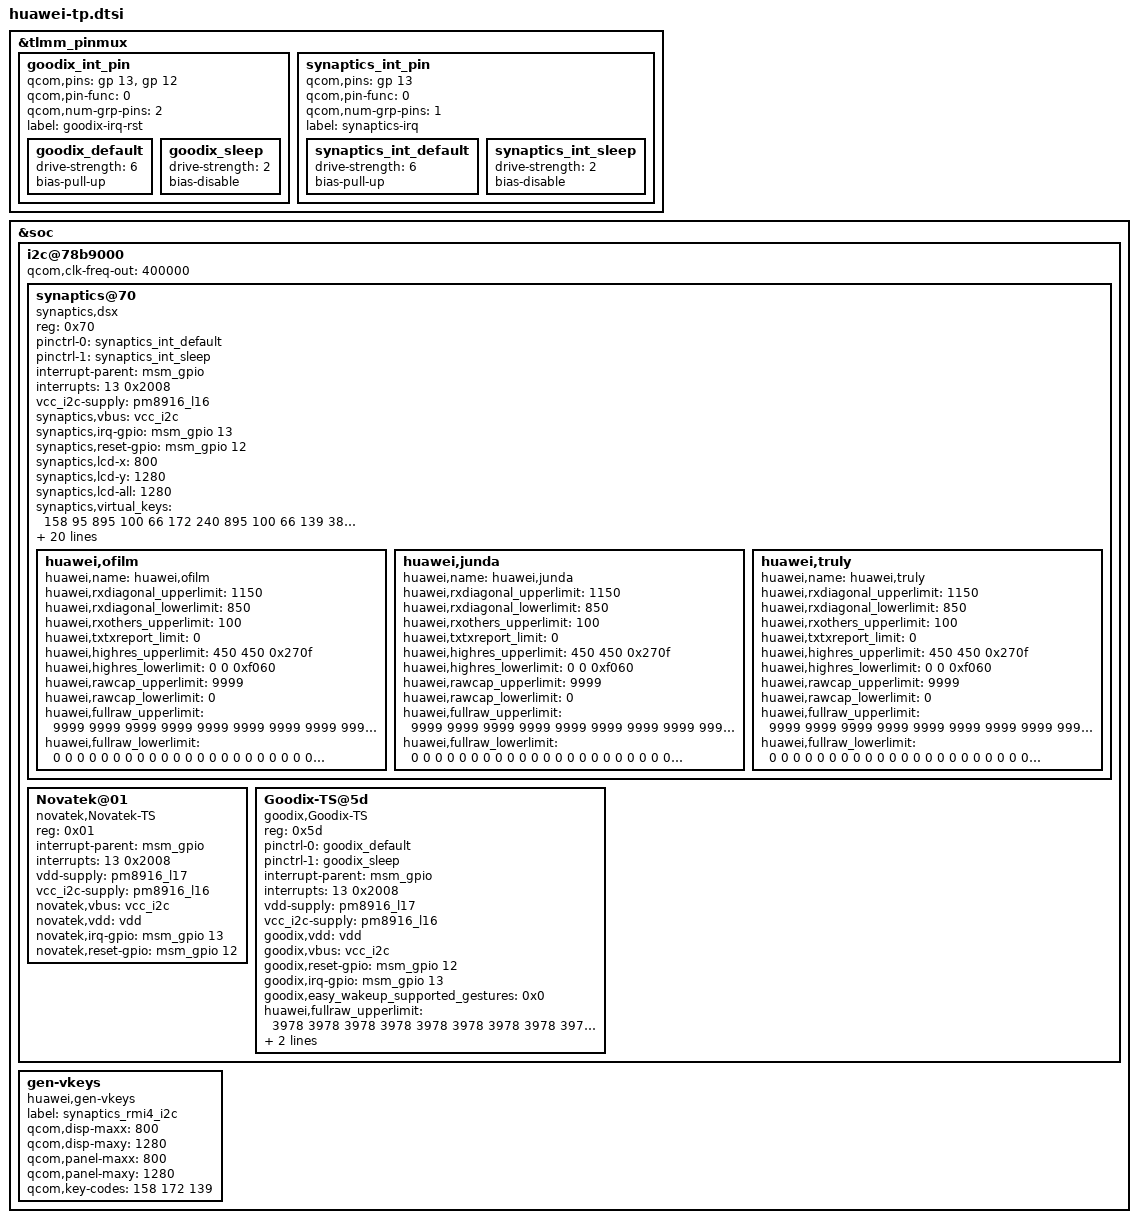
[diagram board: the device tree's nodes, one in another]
/*Add synaptics new driver "Synaptics DSX I2C V2.0"*/
/*Change i2c frepuence from 100kHZ to 400kHZ*/
/*Open fast-relax config for better gesture performance*/
&tlmm_pinmux {

	goodix_int_pin {
		qcom,pins = <&gp 13>,<&gp 12>;
		qcom,pin-func = <0>;
		qcom,num-grp-pins = <2>;
		label = "goodix-irq-rst";
		goodix_default: goodix_default {
			drive-strength = <6>;
			bias-pull-up;
		};
		goodix_sleep: goodix_sleep {
			drive-strength = <2>;
			bias-disable;
		};
	};
	synaptics_int_pin {
		qcom,pins = <&gp 13>;
		qcom,pin-func = <0>;
		qcom,num-grp-pins = <1>;
		label = "synaptics-irq";
		synaptics_int_default: synaptics_int_default {
			drive-strength = <6>;
			bias-pull-up;
		};
		synaptics_int_sleep: synaptics_int_sleep {
			drive-strength = <2>;
			bias-disable;
		};
	};
};
&soc {
	i2c@78b9000 { /* BLSP1 QUP5 */
		status = "ok";
		#address-cells = <1>;
		#size-cells = <0>;
		qcom,clk-freq-out = <400000>;
		synaptics@70 {
			compatible = "synaptics,dsx";
			reg = <0x70>;
			pinctrl-names = "active","sleep";
			pinctrl-0 = <&synaptics_int_default>;
			pinctrl-1 = <&synaptics_int_sleep>;
			interrupt-parent = <&msm_gpio>;
			interrupts = <13 0x2008>;
			/*vdd-supply = <&pm8916_l17>;*/
			vcc_i2c-supply = <&pm8916_l16>;
			/* Some of qcom's param will not be replaced by huawei in dtb, */
			/* just ignore them:such as "pinctrl-names","pinctrl-0","pinctrl-1", */
			/* "synaptics,display-coords","synaptics,panel-coords","synaptics,i2c-pull-up", */
			/* "synaptics,power-down","synaptics,disable-gpios"*/
			/*synaptics,vdd = "vdd";*/
			synaptics,vbus = "vcc_i2c";
			synaptics,irq-gpio = <&msm_gpio 13 0x2008>;
			synaptics,reset-gpio = <&msm_gpio 12 0x0>;
			synaptics,lcd-x = <800>;
			synaptics,lcd-y = <1280>;
			synaptics,lcd-all = <1280>;
			synaptics,virtual_keys = /* KeyCode CenterX CenterY Width Height */
				/* KEY_BACK */
				<158 95 895 100 66
				/* KEY_HOME(172) */
				172 240 895 100 66
				/* KEY_MENU */
				139 385 895 100 66>;

			/* SYNAPTICS_WAKE_UP_GESTURE_FLAG:'1'->enabled,'0'->disabled */
			/*IC flash is not enough for holster,so fw del one gesture*/
			synaptics,gesture_enabled = <0>;
			/* Gestures that supported:                           */
			/* bit0  Double tap                                        */
			/* bit1  Single finger slide from left to right     */
			/* bit2  Single finger slide from right to left     */
			/* bit3  Single finger slide from top to bottom  */
			/* bit4  Single finger slide from bottom to top  */
			/* bit5  Double finger slide from top to bottom--disable for holster*/
			/* bit6  Single finger slide circle                     */
			/* bit7  Single finger write letter c                  */
			/* bit8  Single finger write letter e                  */
			/* bit9  Single finger write letter m                 */
			/* bit10 Single finger write letter w                 */
			/* bit11 Palm off screen                                */
			synaptics,easy_wakeup_supported_gestures = <0xFDF>;

			/*Defination of report key value  for different gestures*/
			synaptics,easy_wakeup_gesture_keys = 
			<	59 /*0.Double tap:KEY_F1*/
				60 /*1.Single finger slide from left to right*/
				61 /*2.Single finger slide from right to left:KEY_F3*/
				62 /*3.Single finger slide from top to bottom*/
				63 /*4.Single finger slide from bottom to top:KEY_F5*/
				64 /*5.Single finger slide circle clockwise*/
				65 /*6.Single finger slide circle counter-clockwise*/
				66 /*7.Single finger write letter c*/
				67 /*8.Single finger write letter e:KEY_F9*/
				68 /*9.Single finger write letter m*/
				87 /*10.Single finger write letter w:KEY_F11*/
				88 /*11.Palm off screen*/
			>;

			/* Double-tap-zone defined by huawei */
			/* Shielded area is:1cm left,1cm right,3cm up,2cm down */
			huawei,dtz_x0 = <77>;
			huawei,dtz_y0 = <233>;
			huawei,dtz_x1 = <403>;
			huawei,dtz_y1 = <699>;

			/* SYNAPTICS_GLOVE_FUNCTION_FLAG:'1'->enabled,'0'->disabled*/
			synaptics,glove_enabled = <0>;
			/*After reduce power-consumption by exit reduce mode,*/
			/*we have to reduce f-r rate to make sure gesture work fine*/
			synaptics,fast_relax_gesture = <30>;
			/*Holster support flag*/
			/*synaptics,holster_supported = <0>;*/
			/*dwt represent doze wakeup threshold in gesture mode*/
			synaptics,ofilm_dwt = <30>;
			synaptics,truly_dwt = <30>;
			synaptics,junda_dwt = <30>;
			synaptics,vdd_ctrl_by_lcd = <1>;

			synaptics,reset-on-status = <0>;
			synaptics,power-delay-ms = <160>;
			synaptics,reset-delay-ms = <100>;
			synaptics,reset-active-ms = <90>;
			synaptics,product_name = "t18p0";

			/*capacitance self-adapt*/
			/*To adjust the cutting angle threshold to the maximum range*/
			huawei,ofilm {
				huawei,name = "huawei,ofilm";
				huawei,rxdiagonal_upperlimit = <1150>;
				huawei,rxdiagonal_lowerlimit = <850>;
				huawei,rxothers_upperlimit = <100>;
				huawei,txtxreport_limit = <0>;
				huawei,highres_upperlimit = <450 450 0x270f>;/*0x270f==9999*/
				huawei,highres_lowerlimit = <0 0 0xf060>;/*0xf060==-4000*/
				huawei,rawcap_upperlimit = <9999>;
				huawei,rawcap_lowerlimit = <0>;

				huawei,fullraw_upperlimit =
					<9999 9999 9999 9999 9999 9999 9999 9999 9999 9999 9999 9999 9999 9999 9999 9999 9999 9999 9999 9999 9999 9999 9999 9999 
					9999 9999 9999 9999 9999 9999 9999 9999 9999 9999 9999 9999 9999 9999 9999 9999 9999 9999 9999 9999 9999 9999 9999 9999 
					9999 9999 9999 9999 9999 9999 9999 9999 9999 9999 9999 9999 9999 9999 9999 9999 9999 9999 9999 9999 9999 9999 9999 9999 
					9999 9999 9999 9999 9999 9999 9999 9999 9999 9999 9999 9999 9999 9999 9999 9999 9999 9999 9999 9999 9999 9999 9999 9999 
					9999 9999 9999 9999 9999 9999 9999 9999 9999 9999 9999 9999 9999 9999 9999 9999 9999 9999 9999 9999 9999 9999 9999 9999 
					9999 9999 9999 9999 9999 9999 9999 9999 9999 9999 9999 9999 9999 9999 9999 9999 9999 9999 9999 9999 9999 9999 9999 9999 
					9999 9999 9999 9999 9999 9999 9999 9999 9999 9999 9999 9999 9999 9999 9999 9999 9999 9999 9999 9999 9999 9999 9999 9999 
					9999 9999 9999 9999 9999 9999 9999 9999 9999 9999 9999 9999 9999 9999 9999 9999 9999 9999 9999 9999 9999 9999 9999 9999 
					9999 9999 9999 9999 9999 9999 9999 9999 9999 9999 9999 9999 9999 9999 9999 9999 9999 9999 9999 9999 9999 9999 9999 9999 
					9999 9999 9999 9999 9999 9999 9999 9999 9999 9999 9999 9999 9999 9999 9999 9999 9999 9999 9999 9999 9999 9999 9999 9999 
					9999 9999 9999 9999 9999 9999 9999 9999 9999 9999 9999 9999 9999 9999 9999 9999 9999 9999 9999 9999 9999 9999 9999 9999 
					9999 9999 9999 9999 9999 9999 9999 9999 9999 9999 9999 9999 9999 9999 9999 9999 9999 9999 9999 9999 9999 9999 9999 9999 
					9999 9999 9999 9999 9999 9999 9999 9999 9999 9999 9999 9999 9999 9999 9999 9999 9999 9999 9999 9999 9999 9999 9999 9999>;

				huawei,fullraw_lowerlimit =
					<0 0 0 0 0 0 0 0 0 0 0 0 0 0 0 0 0 0 0 0 0 0 0 0 
					0 0 0 0 0 0 0 0 0 0 0 0 0 0 0 0 0 0 0 0 0 0 0 0 
					0 0 0 0 0 0 0 0 0 0 0 0 0 0 0 0 0 0 0 0 0 0 0 0 
					0 0 0 0 0 0 0 0 0 0 0 0 0 0 0 0 0 0 0 0 0 0 0 0 
					0 0 0 0 0 0 0 0 0 0 0 0 0 0 0 0 0 0 0 0 0 0 0 0 
					0 0 0 0 0 0 0 0 0 0 0 0 0 0 0 0 0 0 0 0 0 0 0 0 
					0 0 0 0 0 0 0 0 0 0 0 0 0 0 0 0 0 0 0 0 0 0 0 0 
					0 0 0 0 0 0 0 0 0 0 0 0 0 0 0 0 0 0 0 0 0 0 0 0 
					0 0 0 0 0 0 0 0 0 0 0 0 0 0 0 0 0 0 0 0 0 0 0 0 
					0 0 0 0 0 0 0 0 0 0 0 0 0 0 0 0 0 0 0 0 0 0 0 0  
					0 0 0 0 0 0 0 0 0 0 0 0 0 0 0 0 0 0 0 0 0 0 0 0 
					0 0 0 0 0 0 0 0 0 0 0 0 0 0 0 0 0 0 0 0 0 0 0 0 
					0 0 0 0 0 0 0 0 0 0 0 0 0 0 0 0 0 0 0 0 0 0 0 0>;
			};
			huawei,junda {
				huawei,name = "huawei,junda";
				huawei,rxdiagonal_upperlimit = <1150>;
				huawei,rxdiagonal_lowerlimit = <850>;
				huawei,rxothers_upperlimit = <100>;
				huawei,txtxreport_limit = <0>;
				huawei,highres_upperlimit = <450 450 0x270f>;/*0x270f==9999*/
				huawei,highres_lowerlimit = <0 0 0xf060>;/*0xf060==-4000*/
				huawei,rawcap_upperlimit = <9999>;
				huawei,rawcap_lowerlimit = <0>;

				huawei,fullraw_upperlimit =
					<9999 9999 9999 9999 9999 9999 9999 9999 9999 9999 9999 9999 9999 9999 9999 9999 9999 9999 9999 9999 9999 9999 9999 9999 
					9999 9999 9999 9999 9999 9999 9999 9999 9999 9999 9999 9999 9999 9999 9999 9999 9999 9999 9999 9999 9999 9999 9999 9999 
					9999 9999 9999 9999 9999 9999 9999 9999 9999 9999 9999 9999 9999 9999 9999 9999 9999 9999 9999 9999 9999 9999 9999 9999 
					9999 9999 9999 9999 9999 9999 9999 9999 9999 9999 9999 9999 9999 9999 9999 9999 9999 9999 9999 9999 9999 9999 9999 9999 
					9999 9999 9999 9999 9999 9999 9999 9999 9999 9999 9999 9999 9999 9999 9999 9999 9999 9999 9999 9999 9999 9999 9999 9999 
					9999 9999 9999 9999 9999 9999 9999 9999 9999 9999 9999 9999 9999 9999 9999 9999 9999 9999 9999 9999 9999 9999 9999 9999 
					9999 9999 9999 9999 9999 9999 9999 9999 9999 9999 9999 9999 9999 9999 9999 9999 9999 9999 9999 9999 9999 9999 9999 9999 
					9999 9999 9999 9999 9999 9999 9999 9999 9999 9999 9999 9999 9999 9999 9999 9999 9999 9999 9999 9999 9999 9999 9999 9999 
					9999 9999 9999 9999 9999 9999 9999 9999 9999 9999 9999 9999 9999 9999 9999 9999 9999 9999 9999 9999 9999 9999 9999 9999 
					9999 9999 9999 9999 9999 9999 9999 9999 9999 9999 9999 9999 9999 9999 9999 9999 9999 9999 9999 9999 9999 9999 9999 9999 
					9999 9999 9999 9999 9999 9999 9999 9999 9999 9999 9999 9999 9999 9999 9999 9999 9999 9999 9999 9999 9999 9999 9999 9999 
					9999 9999 9999 9999 9999 9999 9999 9999 9999 9999 9999 9999 9999 9999 9999 9999 9999 9999 9999 9999 9999 9999 9999 9999 
					9999 9999 9999 9999 9999 9999 9999 9999 9999 9999 9999 9999 9999 9999 9999 9999 9999 9999 9999 9999 9999 9999 9999 9999>;

				huawei,fullraw_lowerlimit =
					<0 0 0 0 0 0 0 0 0 0 0 0 0 0 0 0 0 0 0 0 0 0 0 0 
					0 0 0 0 0 0 0 0 0 0 0 0 0 0 0 0 0 0 0 0 0 0 0 0 
					0 0 0 0 0 0 0 0 0 0 0 0 0 0 0 0 0 0 0 0 0 0 0 0 
					0 0 0 0 0 0 0 0 0 0 0 0 0 0 0 0 0 0 0 0 0 0 0 0 
					0 0 0 0 0 0 0 0 0 0 0 0 0 0 0 0 0 0 0 0 0 0 0 0 
					0 0 0 0 0 0 0 0 0 0 0 0 0 0 0 0 0 0 0 0 0 0 0 0 
					0 0 0 0 0 0 0 0 0 0 0 0 0 0 0 0 0 0 0 0 0 0 0 0 
					0 0 0 0 0 0 0 0 0 0 0 0 0 0 0 0 0 0 0 0 0 0 0 0 
					0 0 0 0 0 0 0 0 0 0 0 0 0 0 0 0 0 0 0 0 0 0 0 0 
					0 0 0 0 0 0 0 0 0 0 0 0 0 0 0 0 0 0 0 0 0 0 0 0  
					0 0 0 0 0 0 0 0 0 0 0 0 0 0 0 0 0 0 0 0 0 0 0 0 
					0 0 0 0 0 0 0 0 0 0 0 0 0 0 0 0 0 0 0 0 0 0 0 0 
					0 0 0 0 0 0 0 0 0 0 0 0 0 0 0 0 0 0 0 0 0 0 0 0>;
			};
			huawei,truly {
				huawei,name = "huawei,truly";
				huawei,rxdiagonal_upperlimit = <1150>;
				huawei,rxdiagonal_lowerlimit = <850>;
				huawei,rxothers_upperlimit = <100>;
				huawei,txtxreport_limit = <0>;
				huawei,highres_upperlimit = <450 450 0x270f>;/*0x270f==9999*/
				huawei,highres_lowerlimit = <0 0 0xf060>;/*0xf060==-4000*/
				huawei,rawcap_upperlimit = <9999>;
				huawei,rawcap_lowerlimit = <0>;

				huawei,fullraw_upperlimit =
					<9999 9999 9999 9999 9999 9999 9999 9999 9999 9999 9999 9999 9999 9999 9999 9999 9999 9999 9999 9999 9999 9999 9999 9999 
					9999 9999 9999 9999 9999 9999 9999 9999 9999 9999 9999 9999 9999 9999 9999 9999 9999 9999 9999 9999 9999 9999 9999 9999 
					9999 9999 9999 9999 9999 9999 9999 9999 9999 9999 9999 9999 9999 9999 9999 9999 9999 9999 9999 9999 9999 9999 9999 9999 
					9999 9999 9999 9999 9999 9999 9999 9999 9999 9999 9999 9999 9999 9999 9999 9999 9999 9999 9999 9999 9999 9999 9999 9999 
					9999 9999 9999 9999 9999 9999 9999 9999 9999 9999 9999 9999 9999 9999 9999 9999 9999 9999 9999 9999 9999 9999 9999 9999 
					9999 9999 9999 9999 9999 9999 9999 9999 9999 9999 9999 9999 9999 9999 9999 9999 9999 9999 9999 9999 9999 9999 9999 9999 
					9999 9999 9999 9999 9999 9999 9999 9999 9999 9999 9999 9999 9999 9999 9999 9999 9999 9999 9999 9999 9999 9999 9999 9999 
					9999 9999 9999 9999 9999 9999 9999 9999 9999 9999 9999 9999 9999 9999 9999 9999 9999 9999 9999 9999 9999 9999 9999 9999 
					9999 9999 9999 9999 9999 9999 9999 9999 9999 9999 9999 9999 9999 9999 9999 9999 9999 9999 9999 9999 9999 9999 9999 9999 
					9999 9999 9999 9999 9999 9999 9999 9999 9999 9999 9999 9999 9999 9999 9999 9999 9999 9999 9999 9999 9999 9999 9999 9999 
					9999 9999 9999 9999 9999 9999 9999 9999 9999 9999 9999 9999 9999 9999 9999 9999 9999 9999 9999 9999 9999 9999 9999 9999 
					9999 9999 9999 9999 9999 9999 9999 9999 9999 9999 9999 9999 9999 9999 9999 9999 9999 9999 9999 9999 9999 9999 9999 9999 
					9999 9999 9999 9999 9999 9999 9999 9999 9999 9999 9999 9999 9999 9999 9999 9999 9999 9999 9999 9999 9999 9999 9999 9999>;

				huawei,fullraw_lowerlimit =
					<0 0 0 0 0 0 0 0 0 0 0 0 0 0 0 0 0 0 0 0 0 0 0 0 
					0 0 0 0 0 0 0 0 0 0 0 0 0 0 0 0 0 0 0 0 0 0 0 0 
					0 0 0 0 0 0 0 0 0 0 0 0 0 0 0 0 0 0 0 0 0 0 0 0 
					0 0 0 0 0 0 0 0 0 0 0 0 0 0 0 0 0 0 0 0 0 0 0 0 
					0 0 0 0 0 0 0 0 0 0 0 0 0 0 0 0 0 0 0 0 0 0 0 0 
					0 0 0 0 0 0 0 0 0 0 0 0 0 0 0 0 0 0 0 0 0 0 0 0 
					0 0 0 0 0 0 0 0 0 0 0 0 0 0 0 0 0 0 0 0 0 0 0 0 
					0 0 0 0 0 0 0 0 0 0 0 0 0 0 0 0 0 0 0 0 0 0 0 0 
					0 0 0 0 0 0 0 0 0 0 0 0 0 0 0 0 0 0 0 0 0 0 0 0 
					0 0 0 0 0 0 0 0 0 0 0 0 0 0 0 0 0 0 0 0 0 0 0 0  
					0 0 0 0 0 0 0 0 0 0 0 0 0 0 0 0 0 0 0 0 0 0 0 0 
					0 0 0 0 0 0 0 0 0 0 0 0 0 0 0 0 0 0 0 0 0 0 0 0 
					0 0 0 0 0 0 0 0 0 0 0 0 0 0 0 0 0 0 0 0 0 0 0 0>;
			};
		};
		Novatek@01 {
			compatible = "novatek,Novatek-TS";
			reg = <0x01>;
			interrupt-parent = <&msm_gpio>;
			interrupts = <13 0x2008>;
			vdd-supply = <&pm8916_l17>;
			vcc_i2c-supply = <&pm8916_l16>;
			novatek,vbus = "vcc_i2c";
			novatek,vdd = "vdd";
			novatek,irq-gpio = <&msm_gpio 13 0x2008>;
			novatek,reset-gpio = <&msm_gpio 12 0x0>;
		};
	};
	/*Add goodix new driver "gt9xx V1.8"*/
	i2c@78b9000 {
		status = "ok";
		Goodix-TS@5d {
			compatible = "goodix,Goodix-TS";
			reg = <0x5d>;
			pinctrl-names = "default","sleep";
			pinctrl-0 = <&goodix_default>;
			pinctrl-1 = <&goodix_sleep>;
			interrupt-parent = <&msm_gpio>;
			interrupts = <13 0x2008>;
		
			vdd-supply = <&pm8916_l17>;
			vcc_i2c-supply = <&pm8916_l16>;

			goodix,vdd = "vdd";
			goodix,vbus = "vcc_i2c";
			goodix,reset-gpio = <&msm_gpio 12 0x0>;
			goodix,irq-gpio = <&msm_gpio 13 0x2008>;
			goodix,easy_wakeup_supported_gestures = <0x0>;
			
			/*add the rawdata limit for metal mesh */
			huawei,fullraw_upperlimit =
				<3978 3978 3978 3978 3978 3978 3978 3978 3978 3978 3978 3978 3978 3978 3978 3978 3978 3978 3978 3978 
				3978 3978 3978 3978 3978 3978 3978 3978 3978 3978 3978 3978 3978 3978 3978 3978 3978 3978 3978 3978 
				3978 3978 3978 3978 3978 3978 3978 3978 3978 3978 3978 3978 3978 3978 3978 3978 3978 3978 3978 3978 
				3978 3978 3978 3978 3978 3978 3978 3978 3978 3978 3978 3978 3978 3978 3978 3978 3978 3978 3978 3978 
				3978 3978 3978 3978 3978 3978 3978 3978 3978 3978 3978 3978 3978 3978 3978 3978 3978 3978 3978 3978 
				3978 3978 3978 3978 3978 3978 3978 3978 3978 3978 3978 3978 3978 3978 3978 3978 3978 3978 3978 3978 
				3978 3978 3978 3978 3978 3978 3978 3978 3978 3978 3978 3978 3978 3978 3978 3978 3978 3978 3978 3978 
				3978 3978 3978 3978 3978 3978 3978 3978 3978 3978 3978 3978 3978 3978 3978 3978 3978 3978 3978 3978 
				3978 3978 3978 3978 3978 3978 3978 3978 3978 3978 3978 3978 3978 3978 3978 3978 3978 3978 3978 3978 
				3978 3978 3978 3978 3978 3978 3978 3978 3978 3978 3978 3978 3978 3978 3978 3978 3978 3978 3978 9999 >;

			huawei,fullraw_lowerlimit =
				<654 654 654 654 654 654 654 654 654 654 654 654 654 654 654 654 654 654 654 654 
				654 654 654 654 654 654 654 654 654 654 654 654 654 654 654 654 654 654 654 654 
				654 654 654 654 654 654 654 654 654 654 654 654 654 654 654 654 654 654 654 654 
				654 654 654 654 654 654 654 654 654 654 654 654 654 654 654 654 654 654 654 654 
				654 654 654 654 654 654 654 654 654 654 654 654 654 654 654 654 654 654 654 654 
				654 654 654 654 654 654 654 654 654 654 654 654 654 654 654 654 654 654 654 654 
				654 654 654 654 654 654 654 654 654 654 654 654 654 654 654 654 654 654 654 654 
				654 654 654 654 654 654 654 654 654 654 654 654 654 654 654 654 654 654 654 654 
				654 654 654 654 654 654 654 654 654 654 654 654 654 654 654 654 654 654 654 654 
				654 654 654 654 654 654 654 654 654 654 654 654 654 654 654 654 654 654 654 0 >;
		};
	};
	/*To disable gen-vkeys.c probe,avoid generate kobject*/
	gen-vkeys {
		compatible = "huawei,gen-vkeys";
		label = "synaptics_rmi4_i2c";
		qcom,disp-maxx = <800>;
		qcom,disp-maxy = <1280>;
		qcom,panel-maxx = <800>;
		qcom,panel-maxy = <1280>;
		qcom,key-codes = <158 172 139>;
	};

};
